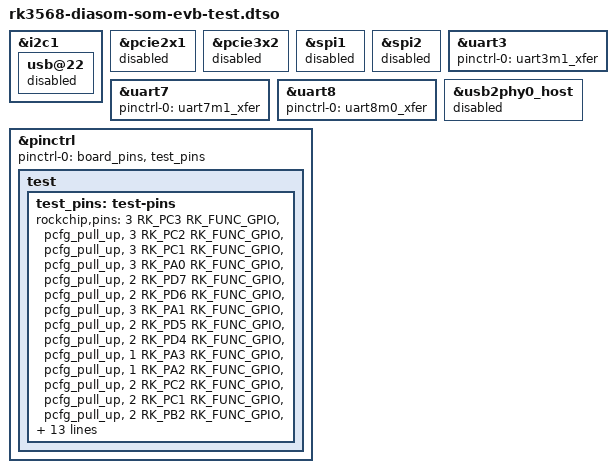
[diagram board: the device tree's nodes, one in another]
/* SPDX-License-Identifier: GPL-2.0+ */
/* SPDX-FileCopyrightText: Alexander Shiyan <shc_work@mail.ru> */

/dts-v1/;
/plugin/;

#include <dt-bindings/pinctrl/rockchip.h>

&i2c1 {
	usb@22 {
		status = "disabled";
	};
};

&pcie2x1 {
	status = "disabled";
};

&pcie3x2 {
	status = "disabled";
};

&spi1 {
	status = "disabled";
};

&spi2 {
	status = "disabled";
};

&uart3 {
	pinctrl-0 = <&uart3m1_xfer>;
};

&uart7 {
	pinctrl-0 = <&uart7m1_xfer>;
};

&uart8 {
	pinctrl-0 = <&uart8m0_xfer>;
};

&usb2phy0_host {
	status = "disabled";
};

&pinctrl {
	pinctrl-0 = <&board_pins &test_pins>;

	test {
		test_pins: test-pins {
			rockchip,pins =
				<3 RK_PC3 RK_FUNC_GPIO &pcfg_pull_up>,	/* spi1_clkm1 */
				<3 RK_PC2 RK_FUNC_GPIO &pcfg_pull_up>,	/* spi1_misom1 */
				<3 RK_PC1 RK_FUNC_GPIO &pcfg_pull_up>,	/* spi1_mosim1 */
				<3 RK_PA0 RK_FUNC_GPIO &pcfg_pull_up>,	/* spi2_clkm1 */
				<2 RK_PD7 RK_FUNC_GPIO &pcfg_pull_up>,	/* spi2_misom1 */
				<2 RK_PD6 RK_FUNC_GPIO &pcfg_pull_up>,	/* spi2_mosim1 */
				<3 RK_PA1 RK_FUNC_GPIO &pcfg_pull_up>,	/* SPI1_CS0 */
				<2 RK_PD5 RK_FUNC_GPIO &pcfg_pull_up>,	/* SPI2_CS0 */
				<2 RK_PD4 RK_FUNC_GPIO &pcfg_pull_up>,	/* SPI2_CS1 */
				<1 RK_PA3 RK_FUNC_GPIO &pcfg_pull_up>,	/* UART3 CTS */
				<1 RK_PA2 RK_FUNC_GPIO &pcfg_pull_up>,	/* UART3 RTS */
				<2 RK_PC2 RK_FUNC_GPIO &pcfg_pull_up>,	/* UART7_CTS */
				<2 RK_PC1 RK_FUNC_GPIO &pcfg_pull_up>,	/* UART7_RTS*/
				<2 RK_PB2 RK_FUNC_GPIO &pcfg_pull_up>,	/* UART8_CTS */
				<2 RK_PB1 RK_FUNC_GPIO &pcfg_pull_up>,	/* UART8_RTS */
				<4 RK_PC4 RK_FUNC_GPIO &pcfg_pull_up>,	/* PCIE30_RESET */
				<4 RK_PC2 RK_FUNC_GPIO &pcfg_pull_up>,	/* PCIE30_CLKREQ */
				<4 RK_PC3 RK_FUNC_GPIO &pcfg_pull_up>,	/* PCIE30_WAKE */
				<3 RK_PD4 RK_FUNC_GPIO &pcfg_pull_up>,	/* PCIE30_CLKIC */
				<3 RK_PD5 RK_FUNC_GPIO &pcfg_pull_up>,	/* PCIE30_PWREN */
				<2 RK_PD0 RK_FUNC_GPIO &pcfg_pull_up>,	/* PCIE20_CLKREQ */
				<2 RK_PD1 RK_FUNC_GPIO &pcfg_pull_up>,	/* PCIE20_WAKE */
				<1 RK_PB1 RK_FUNC_GPIO &pcfg_pull_up>,	/* PCIE20_PERST */
				<3 RK_PD3 RK_FUNC_GPIO &pcfg_pull_up>,	/* PCIE20_PWREN */
				<1 RK_PB2 RK_FUNC_GPIO &pcfg_pull_up>,	/* USB3_HOST1_EN */
				<1 RK_PA5 RK_FUNC_GPIO &pcfg_pull_up>;	/* USB3_OTG0_EN */
		};
	};
};
